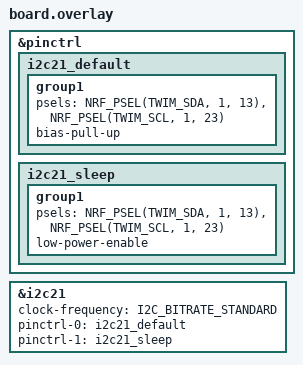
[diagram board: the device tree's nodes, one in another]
// nRF54LM20 DK has USB. Include the main app overlay for USB CDC ACM console and data.
#include "../../../app.overlay"

// I2C bus on P1.13 (SDA) and P1.23 (SCL).
&pinctrl {
	i2c21_default: i2c21_default {
		group1 {
			psels = <NRF_PSEL(TWIM_SDA, 1, 13)>,
				<NRF_PSEL(TWIM_SCL, 1, 23)>;
			bias-pull-up;
		};
	};

	i2c21_sleep: i2c21_sleep {
		group1 {
			psels = <NRF_PSEL(TWIM_SDA, 1, 13)>,
				<NRF_PSEL(TWIM_SCL, 1, 23)>;
			low-power-enable;
		};
	};
};

&i2c21 {
	clock-frequency = <I2C_BITRATE_STANDARD>;
	pinctrl-0 = <&i2c21_default>;
	pinctrl-1 = <&i2c21_sleep>;
	pinctrl-names = "default", "sleep";
	status = "okay";
};
